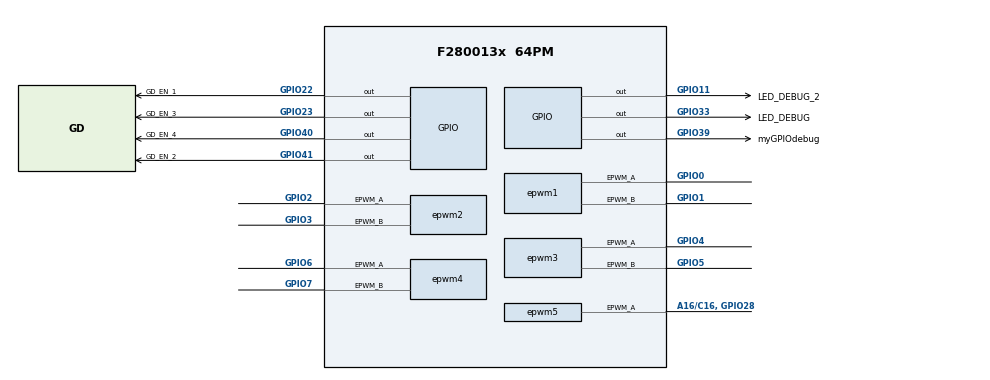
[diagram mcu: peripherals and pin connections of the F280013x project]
/**
 * @cliArgs --device "F280013x" --part "F280013x_64PM" --package "64PM" --context "system" --product "C2000WARE@6.00.01.00"
 * @versions {"tool":"1.26.2+4477"}
 */

/**
 * Import the modules used in this configuration.
 */
const adc         = scripting.addModule("/driverlib/adc.js", {}, false);
const adc1        = adc.addInstance();
const adc2        = adc.addInstance();
const analog      = scripting.addModule("/driverlib/analog.js", {}, false);
const analog1     = analog.addInstance();
const cmpss       = scripting.addModule("/driverlib/cmpss.js", {}, false);
const cmpss1      = cmpss.addInstance();
const cmpss_lite  = scripting.addModule("/driverlib/cmpss_lite.js", {}, false);
const cmpss_lite1 = cmpss_lite.addInstance();
const cmpss_lite2 = cmpss_lite.addInstance();
const cmpss_lite3 = cmpss_lite.addInstance();
const cputimer    = scripting.addModule("/driverlib/cputimer.js", {}, false);
const cputimer1   = cputimer.addInstance();
const epwm        = scripting.addModule("/driverlib/epwm.js", {}, false);
const epwm1       = epwm.addInstance();
const epwm2       = epwm.addInstance();
const epwm3       = epwm.addInstance();
const epwm4       = epwm.addInstance();
const epwm5       = epwm.addInstance();
const epwmxbar    = scripting.addModule("/driverlib/epwmxbar.js", {}, false);
const epwmxbar1   = epwmxbar.addInstance();
const gpio        = scripting.addModule("/driverlib/gpio.js", {}, false);
const gpio1       = gpio.addInstance();
const gpio2       = gpio.addInstance();
const gpio3       = gpio.addInstance();
const gpio4       = gpio.addInstance();
const gpio5       = gpio.addInstance();
const gpio6       = gpio.addInstance();
const gpio7       = gpio.addInstance();
const sync        = scripting.addModule("/driverlib/sync.js");
const sysctl      = scripting.addModule("/driverlib/sysctl.js");

/**
 * Write custom configuration values to the imported modules.
 */
adc1.$name                    = "myADC1";
adc1.adcClockPrescaler        = "ADC_CLK_DIV_4_0";
adc1.enabledSOCs              = ["ADC_SOC_NUMBER0","ADC_SOC_NUMBER1"];
adc1.soc0SampleWindow         = 15;
adc1.soc1SampleWindow         = 15;
adc1.interruptPulseMode       = "ADC_PULSE_END_OF_CONV";
adc1.enabledInts              = ["ADC_INT_NUMBER1"];
adc1.interrupt1SOCSource      = "ADC_SOC_NUMBER1";
adc1.enableInterrupt1         = true;
adc1.registerInterrupts       = ["1"];
adc1.ppb1HighTripLimit        = 1270;
adc1.ppb2SOCNumber            = "ADC_SOC_NUMBER1";
adc1.ppb2HighTripLimit        = 1270;
adc1.ppb1EventInterruptEnable = ["ADC_EVT_TRIPHI"];
adc1.ppb2EventInterruptEnable = ["ADC_EVT_TRIPHI"];
adc1.soc0Channel              = "ADC_CH_ADCIN4";
adc1.soc0Trigger              = "ADC_TRIGGER_EPWM1_SOCA";
adc1.soc1Channel              = "ADC_CH_ADCIN9";
adc1.soc1Trigger              = "ADC_TRIGGER_EPWM1_SOCA";
adc1.adcInt1.$name            = "myADC11_IN";
adc1.adcInt1.interruptHandler = "DAB_Fast_ISR";
adc1.adcInt1.enableInterrupt  = true;

adc2.$name               = "myADC2";
adc2.adcClockPrescaler   = "ADC_CLK_DIV_4_0";
adc2.enabledSOCs         = ["ADC_SOC_NUMBER0","ADC_SOC_NUMBER1"];
adc2.soc0SampleWindow    = 15;
adc2.soc1SampleWindow    = 15;
adc2.interruptPulseMode  = "ADC_PULSE_END_OF_CONV";
adc2.interrupt1SOCSource = "ADC_SOC_NUMBER1";
adc2.enableInterrupt1    = true;
adc2.registerInterrupts  = ["1"];
adc2.adcBase             = "ADCC_BASE";
adc2.enabledPPBs         = ["ADC_PPB_NUMBER1","ADC_PPB_NUMBER2"];
adc2.ppb2SOCNumber       = "ADC_SOC_NUMBER1";
adc2.useInterrupts       = false;
adc2.soc1Channel         = "ADC_CH_ADCIN5";
adc2.soc0Channel         = "ADC_CH_ADCIN9";
adc2.soc0Trigger         = "ADC_TRIGGER_EPWM1_SOCA";
adc2.soc1Trigger         = "ADC_TRIGGER_EPWM1_SOCA";
adc2.ppb2ReferenceOffset = 2048;
adc2.ppb1ReferenceOffset = 2033;

cmpss1.$name              = "myCMPSS1";
cmpss1.hysteresisVal      = "2";
cmpss1.highCTRIPOUT       = "CMPSS_TRIPOUT_FILTER";
cmpss1.highCTRIP          = "CMPSS_TRIP_FILTER";
cmpss1.samplePrescaleHigh = 1;
cmpss1.sampleWindowHigh   = 5;
cmpss1.thresholdHigh      = 4;
cmpss1.lowCompInvert      = true;
cmpss1.lowCTRIPOUT        = "CMPSS_TRIPOUT_FILTER";
cmpss1.lowCTRIP           = "CMPSS_TRIP_FILTER";
cmpss1.samplePrescaleLow  = 1;
cmpss1.sampleWindowLow    = 5;
cmpss1.thresholdLow       = 4;
cmpss1.enableModule       = true;
cmpss1.dacValHigh         = 2175;
cmpss1.initFilterHigh     = true;
cmpss1.initFilterLow      = true;
cmpss1.dacValLow          = 1927;

cmpss_lite1.cmpssLiteBase       = "CMPSSLITE3_BASE";
cmpss_lite1.highCTRIPOUT        = "CMPSS_TRIPOUT_FILTER";
cmpss_lite1.highCTRIP           = "CMPSS_TRIP_FILTER";
cmpss_lite1.hysteresisVal       = "2";
cmpss_lite1.asysCMPHPMXSELValue = "3";
cmpss_lite1.lowCompInvert       = true;
cmpss_lite1.samplePrescaleLow   = 1;
cmpss_lite1.sampleWindowLow     = 5;
cmpss_lite1.thresholdLow        = 4;
cmpss_lite1.samplePrescaleHigh  = 1;
cmpss_lite1.sampleWindowHigh    = 5;
cmpss_lite1.thresholdHigh       = 4;
cmpss_lite1.asysCMPLPMXSELValue = "3";
cmpss_lite1.$name               = "myCMPSS3";
cmpss_lite1.enableModule        = true;
cmpss_lite1.dacValHigh          = 2175;
cmpss_lite1.dacValLow           = 1927;
cmpss_lite1.initFilterLow       = true;
cmpss_lite1.initFilterHigh      = true;

cmpss_lite2.$name              = "myCMPSS2";
cmpss_lite2.samplePrescaleHigh = 1;
cmpss_lite2.sampleWindowHigh   = 5;
cmpss_lite2.thresholdHigh      = 4;
cmpss_lite2.dacValHigh         = 1150;

cmpss_lite3.$name              = "myCMPSS4";
cmpss_lite3.samplePrescaleHigh = 1;
cmpss_lite3.sampleWindowHigh   = 5;
cmpss_lite3.thresholdHigh      = 4;
cmpss_lite3.cmpssLiteBase      = "CMPSSLITE4_BASE";
cmpss_lite3.initFilterHigh     = true;
cmpss_lite3.dacValHigh         = 1150;

analog1.$name            = "myANALOGPinMux0";
adc1.analog              = analog1;
adc2.analog              = analog1;
cmpss1.analog            = analog1;
cmpss_lite1.analog       = analog1;
analog1.useCase          = "CUSTOM";
analog1.useInterfacePins = ["A0/C15/CMP1_DACL","A1","A10/C10, GPIO230","A11/C0","A12/C1","A15/C7","A17/C17, GPIO20","A18/C18, GPIO21","A19/C19, GPIO13","A2/C9, GPIO224","A20/C20, GPIO12","A3/C5, GPIO242","A4/C14","A5/C2","A6, GPIO228","A7/C3","A8/C11","C4/A14","C6, GPIO226","C8/A9, GPIO227"];
cmpss_lite2.analog       = analog1;
cmpss_lite3.analog       = analog1;

cputimer1.$name          = "myCPUTIMER0";
cputimer1.timerPeriod    = 4294967295;
cputimer1.timerPrescaler = 1;
cputimer1.startTimer     = true;

epwm1.$name                                                      = "myEPWM1";
epwm1.epwmTimebase_hsClockDiv                                    = "EPWM_HSCLOCK_DIVIDER_1";
epwm1.epwmTimebase_period                                        = 240;
epwm1.epwmTimebase_syncInPulseSource                             = "EPWM_SYNC_IN_PULSE_SRC_DISABLE";
epwm1.epwmTimebase_syncOutPulseMode                              = ["EPWM_SYNC_OUT_PULSE_ON_CNTR_ZERO"];
epwm1.epwmCounterCompare_cmpA                                    = 120;
epwm1.epwmCounterCompare_cmpB                                    = 120;
epwm1.epwmActionQualifier_EPWM_AQ_OUTPUT_A_ON_TIMEBASE_UP_CMPA   = "EPWM_AQ_OUTPUT_HIGH";
epwm1.epwmActionQualifier_EPWM_AQ_OUTPUT_A_ON_TIMEBASE_DOWN_CMPA = "EPWM_AQ_OUTPUT_LOW";
epwm1.epwmDeadband_enableRED                                     = true;
epwm1.epwmDeadband_enableFED                                     = true;
epwm1.epwmDeadband_polarityFED                                   = "EPWM_DB_POLARITY_ACTIVE_LOW";
epwm1.epwmEventTrigger_EPWM_SOC_A_triggerEnable                  = true;
epwm1.epwmEventTrigger_EPWM_SOC_A_triggerEventPrescalar          = "5";
epwm1.epwmTimebase_counterMode                                   = "EPWM_COUNTER_MODE_UP_DOWN";
epwm1.epwmTimebase_counterModeAfterSync                          = "EPWM_COUNT_MODE_UP_AFTER_SYNC";
epwm1.epwmDigitalCompare_EPWM_DC_TYPE_DCAH                       = "EPWM_DC_TRIP_TRIPIN4";
epwm1.epwmDigitalCompare_EPWM_TZ_DC_OUTPUT_A1                    = "EPWM_TZ_EVENT_DCXH_HIGH";
epwm1.epwmTripZone_EPWM_TZ_ACTION_EVENT_TZA                      = "EPWM_TZ_ACTION_LOW";
epwm1.epwmTripZone_EPWM_TZ_ACTION_EVENT_TZB                      = "EPWM_TZ_ACTION_LOW";
epwm1.epwmTripZone_EPWM_TZ_ACTION_EVENT_DCAEVT1                  = "EPWM_TZ_ACTION_LOW";
epwm1.epwmTripZone_EPWM_TZ_ACTION_EVENT_DCAEVT2                  = "EPWM_TZ_ACTION_LOW";
epwm1.epwmTripZone_oneShotSource                                 = ["EPWM_TZ_SIGNAL_DCAEVT1"];
epwm1.epwmTripZone_EPWM_TZ_ACTION_EVENT_DCBEVT1                  = "EPWM_TZ_ACTION_LOW";
epwm1.epwmTripZone_EPWM_TZ_ACTION_EVENT_DCBEVT2                  = "EPWM_TZ_ACTION_LOW";
epwm1.epwmEventTrigger_EPWM_SOC_A_triggerSource                  = "EPWM_SOC_TBCTR_PERIOD";
epwm1.epwm.$assign                                               = "EPWM1";
epwm1.epwm.epwm_aPin.$assign                                     = "GPIO0";
epwm1.epwm.epwm_bPin.$assign                                     = "GPIO1";

epwm2.epwmTimebase_hsClockDiv                                    = "EPWM_HSCLOCK_DIVIDER_1";
epwm2.epwmTimebase_period                                        = 240;
epwm2.epwmCounterCompare_cmpA                                    = 120;
epwm2.epwmCounterCompare_cmpB                                    = 120;
epwm2.epwmDeadband_enableRED                                     = true;
epwm2.epwmDeadband_enableFED                                     = true;
epwm2.epwmDeadband_polarityFED                                   = "EPWM_DB_POLARITY_ACTIVE_LOW";
epwm2.$name                                                      = "myEPWM2";
epwm2.epwmTimebase_counterMode                                   = "EPWM_COUNTER_MODE_UP_DOWN";
epwm2.epwmTimebase_counterModeAfterSync                          = "EPWM_COUNT_MODE_UP_AFTER_SYNC";
epwm2.epwmActionQualifier_EPWM_AQ_OUTPUT_A_ON_TIMEBASE_UP_CMPA   = "EPWM_AQ_OUTPUT_LOW";
epwm2.epwmActionQualifier_EPWM_AQ_OUTPUT_A_ON_TIMEBASE_DOWN_CMPA = "EPWM_AQ_OUTPUT_HIGH";
epwm2.epwmTimebase_phaseEnable                                   = true;
epwm2.epwmTripZone_EPWM_TZ_ACTION_EVENT_TZA                      = "EPWM_TZ_ACTION_LOW";
epwm2.epwmTripZone_EPWM_TZ_ACTION_EVENT_TZB                      = "EPWM_TZ_ACTION_LOW";
epwm2.epwmTripZone_EPWM_TZ_ACTION_EVENT_DCAEVT1                  = "EPWM_TZ_ACTION_LOW";
epwm2.epwmTripZone_EPWM_TZ_ACTION_EVENT_DCAEVT2                  = "EPWM_TZ_ACTION_LOW";
epwm2.epwmTripZone_EPWM_TZ_ACTION_EVENT_DCBEVT1                  = "EPWM_TZ_ACTION_LOW";
epwm2.epwmTripZone_EPWM_TZ_ACTION_EVENT_DCBEVT2                  = "EPWM_TZ_ACTION_LOW";
epwm2.epwmTripZone_oneShotSource                                 = ["EPWM_TZ_SIGNAL_DCAEVT1"];
epwm2.epwmDigitalCompare_EPWM_DC_TYPE_DCAH                       = "EPWM_DC_TRIP_TRIPIN4";
epwm2.epwmDigitalCompare_EPWM_TZ_DC_OUTPUT_A1                    = "EPWM_TZ_EVENT_DCXH_HIGH";
epwm2.epwm.$assign                                               = "EPWM2";
epwm2.epwm.epwm_aPin.$assign                                     = "GPIO2";
epwm2.epwm.epwm_bPin.$assign                                     = "GPIO3";

epwm3.epwmTimebase_hsClockDiv                                    = "EPWM_HSCLOCK_DIVIDER_1";
epwm3.epwmTimebase_period                                        = 240;
epwm3.epwmCounterCompare_cmpA                                    = 120;
epwm3.epwmCounterCompare_cmpB                                    = 120;
epwm3.epwmDeadband_enableRED                                     = true;
epwm3.epwmDeadband_enableFED                                     = true;
epwm3.epwmDeadband_polarityFED                                   = "EPWM_DB_POLARITY_ACTIVE_LOW";
epwm3.$name                                                      = "myEPWM3";
epwm3.epwmTimebase_counterMode                                   = "EPWM_COUNTER_MODE_UP_DOWN";
epwm3.epwmTimebase_counterModeAfterSync                          = "EPWM_COUNT_MODE_UP_AFTER_SYNC";
epwm3.epwmActionQualifier_EPWM_AQ_OUTPUT_A_ON_TIMEBASE_UP_CMPA   = "EPWM_AQ_OUTPUT_HIGH";
epwm3.epwmActionQualifier_EPWM_AQ_OUTPUT_A_ON_TIMEBASE_DOWN_CMPA = "EPWM_AQ_OUTPUT_LOW";
epwm3.epwmTimebase_phaseEnable                                   = true;
epwm3.epwmTripZone_EPWM_TZ_ACTION_EVENT_TZA                      = "EPWM_TZ_ACTION_LOW";
epwm3.epwmTripZone_EPWM_TZ_ACTION_EVENT_TZB                      = "EPWM_TZ_ACTION_LOW";
epwm3.epwmTripZone_EPWM_TZ_ACTION_EVENT_DCAEVT1                  = "EPWM_TZ_ACTION_LOW";
epwm3.epwmTripZone_EPWM_TZ_ACTION_EVENT_DCAEVT2                  = "EPWM_TZ_ACTION_LOW";
epwm3.epwmTripZone_EPWM_TZ_ACTION_EVENT_DCBEVT1                  = "EPWM_TZ_ACTION_LOW";
epwm3.epwmTripZone_EPWM_TZ_ACTION_EVENT_DCBEVT2                  = "EPWM_TZ_ACTION_LOW";
epwm3.epwmDigitalCompare_EPWM_DC_TYPE_DCAH                       = "EPWM_DC_TRIP_TRIPIN4";
epwm3.epwmDigitalCompare_EPWM_TZ_DC_OUTPUT_A1                    = "EPWM_TZ_EVENT_DCXH_HIGH";
epwm3.epwmTripZone_oneShotSource                                 = ["EPWM_TZ_SIGNAL_DCAEVT1"];
epwm3.epwm.$assign                                               = "EPWM3";
epwm3.epwm.epwm_aPin.$assign                                     = "GPIO4";
epwm3.epwm.epwm_bPin.$assign                                     = "GPIO5";

epwm4.epwmTimebase_hsClockDiv                                    = "EPWM_HSCLOCK_DIVIDER_1";
epwm4.epwmTimebase_period                                        = 240;
epwm4.epwmCounterCompare_cmpA                                    = 120;
epwm4.epwmCounterCompare_cmpB                                    = 120;
epwm4.epwmDeadband_enableRED                                     = true;
epwm4.epwmDeadband_enableFED                                     = true;
epwm4.epwmDeadband_polarityFED                                   = "EPWM_DB_POLARITY_ACTIVE_LOW";
epwm4.$name                                                      = "myEPWM4";
epwm4.epwmTimebase_counterMode                                   = "EPWM_COUNTER_MODE_UP_DOWN";
epwm4.epwmTimebase_counterModeAfterSync                          = "EPWM_COUNT_MODE_UP_AFTER_SYNC";
epwm4.epwmActionQualifier_EPWM_AQ_OUTPUT_A_ON_TIMEBASE_UP_CMPA   = "EPWM_AQ_OUTPUT_LOW";
epwm4.epwmActionQualifier_EPWM_AQ_OUTPUT_A_ON_TIMEBASE_DOWN_CMPA = "EPWM_AQ_OUTPUT_HIGH";
epwm4.epwmTimebase_phaseEnable                                   = true;
epwm4.epwmTripZone_EPWM_TZ_ACTION_EVENT_TZA                      = "EPWM_TZ_ACTION_LOW";
epwm4.epwmTripZone_EPWM_TZ_ACTION_EVENT_TZB                      = "EPWM_TZ_ACTION_LOW";
epwm4.epwmTripZone_EPWM_TZ_ACTION_EVENT_DCAEVT1                  = "EPWM_TZ_ACTION_LOW";
epwm4.epwmTripZone_EPWM_TZ_ACTION_EVENT_DCAEVT2                  = "EPWM_TZ_ACTION_LOW";
epwm4.epwmTripZone_EPWM_TZ_ACTION_EVENT_DCBEVT1                  = "EPWM_TZ_ACTION_LOW";
epwm4.epwmTripZone_EPWM_TZ_ACTION_EVENT_DCBEVT2                  = "EPWM_TZ_ACTION_LOW";
epwm4.epwmDigitalCompare_EPWM_DC_TYPE_DCAH                       = "EPWM_DC_TRIP_TRIPIN4";
epwm4.epwmDigitalCompare_EPWM_TZ_DC_OUTPUT_A1                    = "EPWM_TZ_EVENT_DCXH_HIGH";
epwm4.epwmTripZone_oneShotSource                                 = ["EPWM_TZ_SIGNAL_DCAEVT1"];
epwm4.epwm.$assign                                               = "EPWM4";
epwm4.epwm.epwm_aPin.$assign                                     = "GPIO6";
epwm4.epwm.epwm_bPin.$assign                                     = "GPIO7";

epwm5.$name                                                      = "myEPWM7";
epwm5.epwmTimebase_period                                        = 240;
epwm5.epwmTimebase_counterMode                                   = "EPWM_COUNTER_MODE_UP_DOWN";
epwm5.epwmTimebase_hsClockDiv                                    = "EPWM_HSCLOCK_DIVIDER_1";
epwm5.epwmActionQualifier_EPWM_AQ_OUTPUT_B_ON_TIMEBASE_UP_CMPB   = "EPWM_AQ_OUTPUT_HIGH";
epwm5.epwmActionQualifier_EPWM_AQ_OUTPUT_B_ON_TIMEBASE_DOWN_CMPB = "EPWM_AQ_OUTPUT_LOW";
epwm5.epwmTripZone_EPWM_TZ_ACTION_EVENT_TZA                      = "EPWM_TZ_ACTION_LOW";
epwm5.epwmTripZone_EPWM_TZ_ACTION_EVENT_TZB                      = "EPWM_TZ_ACTION_LOW";
epwm5.epwmTripZone_EPWM_TZ_ACTION_EVENT_DCAEVT1                  = "EPWM_TZ_ACTION_LOW";
epwm5.epwmTripZone_EPWM_TZ_ACTION_EVENT_DCAEVT2                  = "EPWM_TZ_ACTION_LOW";
epwm5.epwmTripZone_EPWM_TZ_ACTION_EVENT_DCBEVT1                  = "EPWM_TZ_ACTION_LOW";
epwm5.epwmTripZone_EPWM_TZ_ACTION_EVENT_DCBEVT2                  = "EPWM_TZ_ACTION_LOW";
epwm5.epwmTripZone_oneShotSource                                 = ["EPWM_TZ_SIGNAL_DCAEVT1"];
epwm5.epwmDigitalCompare_EPWM_DC_TYPE_DCAH                       = "EPWM_DC_TRIP_TRIPIN4";
epwm5.epwmDigitalCompare_EPWM_TZ_DC_OUTPUT_A1                    = "EPWM_TZ_EVENT_DCXH_HIGH";
epwm5.epwm.$assign                                               = "EPWM7";
epwm5.epwm.epwm_aPin.$assign                                     = "A16/C16, GPIO28";

epwmxbar1.$name       = "myEPWMXBAR0";
epwmxbar1.mux4Config  = "XBAR_EPWM_MUX04_CMPSS3_CTRIPH_OR_L";
epwmxbar1.mux0Config  = "XBAR_EPWM_MUX00_ECAP1_OUT";
epwmxbar1.mux1Config  = "XBAR_EPWM_MUX01_INPUTXBAR1";
epwmxbar1.mux2Config  = "XBAR_EPWM_MUX02_ECAP2_OUT";
epwmxbar1.mux3Config  = "XBAR_EPWM_MUX03_INPUTXBAR2";
epwmxbar1.mux5Config  = "XBAR_EPWM_MUX05_INPUTXBAR3";
epwmxbar1.mux6Config  = "XBAR_EPWM_MUX06_CMPSS4_CTRIPH_OR_L";
epwmxbar1.mux7Config  = "XBAR_EPWM_MUX07_INPUTXBAR4";
epwmxbar1.mux31Config = "XBAR_EPWM_MUX31_INPUTXBAR14";

gpio1.$name             = "LED_DEBUG";
gpio1.direction         = "GPIO_DIR_MODE_OUT";
gpio1.writeInitialValue = true;
gpio1.gpioPin.$assign   = "GPIO33";

gpio2.$name             = "GD_EN_1";
gpio2.writeInitialValue = true;
gpio2.initialValue      = 1;
gpio2.padConfig         = "PULLUP";
gpio2.direction         = "GPIO_DIR_MODE_OUT";
gpio2.gpioPin.$assign   = "GPIO22";

gpio3.$name             = "GD_EN_2";
gpio3.direction         = "GPIO_DIR_MODE_OUT";
gpio3.writeInitialValue = true;
gpio3.initialValue      = 1;
gpio3.padConfig         = "PULLUP";
gpio3.gpioPin.$assign   = "GPIO41";

gpio4.$name             = "GD_EN_3";
gpio4.direction         = "GPIO_DIR_MODE_OUT";
gpio4.writeInitialValue = true;
gpio4.initialValue      = 1;
gpio4.padConfig         = "PULLUP";
gpio4.gpioPin.$assign   = "GPIO23";

gpio5.$name             = "GD_EN_4";
gpio5.direction         = "GPIO_DIR_MODE_OUT";
gpio5.writeInitialValue = true;
gpio5.initialValue      = 1;
gpio5.padConfig         = "PULLUP";
gpio5.gpioPin.$assign   = "GPIO40";

gpio6.$name             = "myGPIOdebug";
gpio6.direction         = "GPIO_DIR_MODE_OUT";
gpio6.writeInitialValue = true;
gpio6.gpioPin.$assign   = "GPIO39";

gpio7.$name           = "LED_DEBUG_2";
gpio7.direction       = "GPIO_DIR_MODE_OUT";
gpio7.gpioPin.$assign = "GPIO11";

sync.ADCSOCAOutputSelect = ["SYSCTL_ADCSOC_SRC_PWM1SOCA"];

sysctl.enable_SYSCTL_PERIPH_CLK_TBCLKSYNC = true;

/**
 * Pinmux solution for unlocked pins/peripherals. This ensures that minor changes to the automatic solver in a future
 * version of the tool will not impact the pinmux you originally saw.  These lines can be completely deleted in order to
 * re-solve from scratch.
 */
analog1.analog.$suggestSolution                        = "ANALOG";
analog1.analog["a0/c15/cmp1_daclPin"].$suggestSolution = "A0/C15/CMP1_DACL";
analog1.analog.a1Pin.$suggestSolution                  = "A1";
analog1.analog["a10/c10, gpio230Pin"].$suggestSolution = "A10/C10, GPIO230";
analog1.analog["a11/c0Pin"].$suggestSolution           = "A11/C0";
analog1.analog["a12/c1Pin"].$suggestSolution           = "A12/C1";
analog1.analog["a15/c7Pin"].$suggestSolution           = "A15/C7";
analog1.analog["a17/c17, gpio20Pin"].$suggestSolution  = "A17/C17, GPIO20";
analog1.analog["a18/c18, gpio21Pin"].$suggestSolution  = "A18/C18, GPIO21";
analog1.analog["a19/c19, gpio13Pin"].$suggestSolution  = "A19/C19, GPIO13";
analog1.analog["a2/c9, gpio224Pin"].$suggestSolution   = "A2/C9, GPIO224";
analog1.analog["a20/c20, gpio12Pin"].$suggestSolution  = "A20/C20, GPIO12";
analog1.analog["a3/c5, gpio242Pin"].$suggestSolution   = "A3/C5, GPIO242";
analog1.analog["a4/c14Pin"].$suggestSolution           = "A4/C14";
analog1.analog["a5/c2Pin"].$suggestSolution            = "A5/C2";
analog1.analog["a6, gpio228Pin"].$suggestSolution      = "A6, GPIO228";
analog1.analog["a7/c3Pin"].$suggestSolution            = "A7/C3";
analog1.analog["a8/c11Pin"].$suggestSolution           = "A8/C11";
analog1.analog["c4/a14Pin"].$suggestSolution           = "C4/A14";
analog1.analog["c6, gpio226Pin"].$suggestSolution      = "C6, GPIO226";
analog1.analog["c8/a9, gpio227Pin"].$suggestSolution   = "C8/A9, GPIO227";
epwm5.epwm.epwm_bPin.$suggestSolution                  = "GPIO29";
